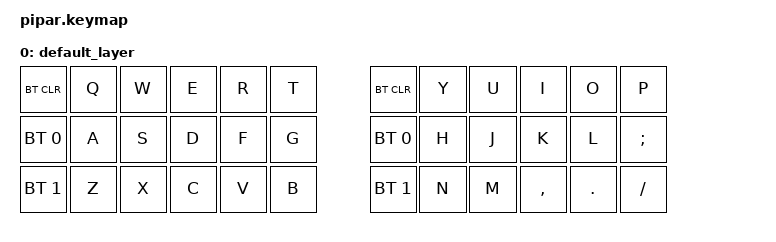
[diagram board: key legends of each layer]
#include <behaviors.dtsi>
#include <dt-bindings/zmk/keys.h>
#include <dt-bindings/zmk/bt.h>

/ {
        keymap {
                compatible = "zmk,keymap";

                default_layer {
// -----------------------------------------------------------------------------------------
// |  BT_CLR    |  Q  |  W  |  E  |  R  |  T   |   |  BT_CLR    |  Y  |  U   |  I  |  O  |  P  |
// |  BT_SEL 0  |  A  |  S  |  D  |  F  |  G   |   |  BT_SEL 0  |  H  |  J   |  K  |  L  |  ;  |
// |  BT_SEL 1  |  Z  |  X  |  C  |  V  |  B   |   |  BT_SEL 1  |  N  |  M   |  ,  |  .  |  /  |
                        bindings = <
   &bt BT_CLR   &kp Q &kp W &kp E &kp R &kp T           &bt BT_CLR   &kp Y &kp U  &kp I     &kp O   &kp P
   &bt BT_SEL 0 &kp A &kp S &kp D &kp F &kp G           &bt BT_SEL 0 &kp H &kp J  &kp K     &kp L   &kp SEMI
   &bt BT_SEL 1 &kp Z &kp X &kp C &kp V &kp B           &bt BT_SEL 1 &kp N &kp M  &kp COMMA &kp DOT &kp FSLH
                        >;
                };
        };
};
